VERSION ""

NS_ :

BS_:

BU_: VCU BMS Motor MCU CANoe

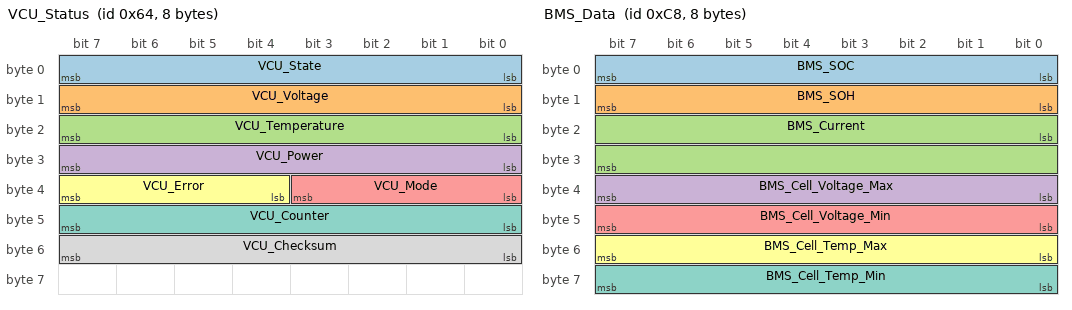
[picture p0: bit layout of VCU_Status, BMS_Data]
BO_ 100 VCU_Status: 8 VCU
 SG_ VCU_State : 0|8@1+ (0.1,0) [0|25.5] "V" Vector__XXX
 SG_ VCU_Voltage : 8|8@1+ (0.1,0) [0|25.5] "V" Vector__XXX
 SG_ VCU_Temperature : 16|8@1+ (1,-40) [-40|215] "degC" Vector__XXX
 SG_ VCU_Power : 24|8@1+ (0.5,0) [0|127.5] "kW" Vector__XXX
 SG_ VCU_Mode : 32|4@1+ (1,0) [0|15] "" Vector__XXX
 SG_ VCU_Error : 36|4@1+ (1,0) [0|15] "" Vector__XXX
 SG_ VCU_Counter : 40|8@1+ (1,0) [0|255] "" Vector__XXX
 SG_ VCU_Checksum : 48|8@1+ (1,0) [0|255] "" Vector__XXX

BO_ 200 BMS_Data: 8 BMS
 SG_ BMS_SOC : 0|8@1+ (1,0) [0|100] "%" Vector__XXX
 SG_ BMS_SOH : 8|8@1+ (1,0) [0|100] "%" Vector__XXX
 SG_ BMS_Current : 16|16@1- (0.1,-3276.8) [-3276.8|3276.7] "A" Vector__XXX
 SG_ BMS_Cell_Voltage_Max : 32|8@1+ (0.01,0) [0|2.55] "V" Vector__XXX
 SG_ BMS_Cell_Voltage_Min : 40|8@1+ (0.01,0) [0|2.55] "V" Vector__XXX
 SG_ BMS_Cell_Temp_Max : 48|8@1+ (1,-40) [-40|215] "degC" Vector__XXX
 SG_ BMS_Cell_Temp_Min : 56|8@1+ (1,-40) [-40|215] "degC" Vector__XXX

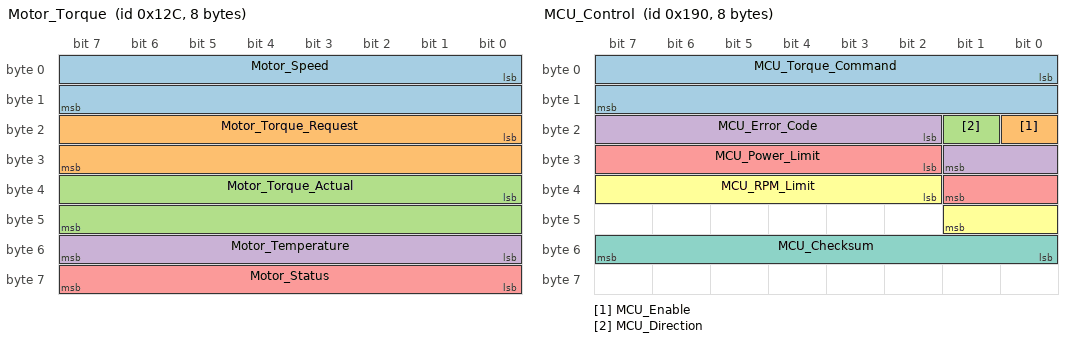
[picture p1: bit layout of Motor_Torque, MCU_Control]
BO_ 300 Motor_Torque: 8 Motor
 SG_ Motor_Speed : 0|16@1+ (1,0) [0|65535] "rpm" Vector__XXX
 SG_ Motor_Torque_Request : 16|16@1- (0.1,-3276.8) [-3276.8|3276.7] "Nm" Vector__XXX
 SG_ Motor_Torque_Actual : 32|16@1- (0.1,-3276.8) [-3276.8|3276.7] "Nm" Vector__XXX
 SG_ Motor_Temperature : 48|8@1+ (1,-40) [-40|215] "degC" Vector__XXX
 SG_ Motor_Status : 56|8@1+ (1,0) [0|255] "" Vector__XXX

BO_ 400 MCU_Control: 8 MCU
 SG_ MCU_Torque_Command : 0|16@1- (0.1,-3276.8) [-3276.8|3276.7] "Nm" Vector__XXX
 SG_ MCU_Enable : 16|1@1+ (1,0) [0|1] "" Vector__XXX
 SG_ MCU_Direction : 17|1@1+ (1,0) [0|1] "" Vector__XXX
 SG_ MCU_Error_Code : 18|8@1+ (1,0) [0|255] "" Vector__XXX
 SG_ MCU_Power_Limit : 26|8@1+ (0.5,0) [0|127.5] "kW" Vector__XXX
 SG_ MCU_RPM_Limit : 34|8@1+ (100,0) [0|25500] "rpm" Vector__XXX
 SG_ MCU_Checksum : 48|8@1+ (1,0) [0|255] "" Vector__XXX

VAL_ 100 VCU_State 0 "OFF" 1 "STANDBY" 2 "READY" 3 "DRIVE" 4 "CHARGE" 5 "FAULT" 6 "SLEEP" ;
VAL_ 100 VCU_Mode 0 "MANUAL" 1 "AUTO" 2 "SPORT" 3 "ECO" ;
VAL_ 300 Motor_Status 0 "STOPPED" 1 "RUNNING" 2 "FAULT" 3 "INIT" ;

CM_ BO_ 100 "VCU status message - contains state, voltage, temperature, power and mode information";
CM_ BO_ 200 "BMS data message - contains SOC, SOH, current and cell information";
CM_ BO_ 300 "Motor torque message - contains speed, torque request/actual and temperature";
CM_ BO_ 400 "MCU control message - contains torque command, enable, direction and limits";

BA_DEF_ BO_  "GenMsgCycleTime" INT 0 500000;
BA_DEF_DEF_  "GenMsgCycleTime" 0;

BA_ "GenMsgCycleTime" BO_ 100 100;
BA_ "GenMsgCycleTime" BO_ 200 100;
BA_ "GenMsgCycleTime" BO_ 300 50;
BA_ "GenMsgCycleTime" BO_ 400 10;
